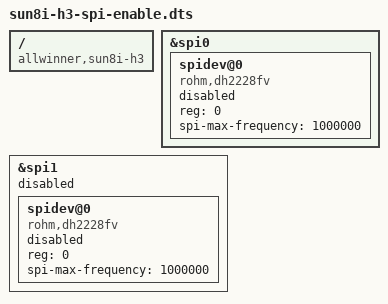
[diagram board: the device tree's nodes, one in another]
/dts-v1/;
/plugin/;

/ {
    compatible = "allwinner,sun8i-h3";

    fragment@0 {
        target = <&spi0>;
        __overlay__ {
            status = "okay";
            #address-cells = <1>;
            #size-cells = <0>;

            spidev@0 {
                compatible = "rohm,dh2228fv"; // Use this instead of "spidev"
                status = "disabled";
                reg = <0>;
                spi-max-frequency = <1000000>;
            };
        };
    };

    fragment@1 {
        target = <&spi1>;
        __overlay__ {
            status = "disabled";
            #address-cells = <1>;
            #size-cells = <0>;

            spidev@0 {
                compatible = "rohm,dh2228fv";
                status = "disabled";
                reg = <0>;
                spi-max-frequency = <1000000>;
            };
        };
    };
};
